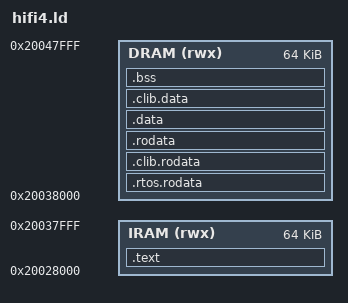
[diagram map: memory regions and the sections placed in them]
/* $Id$ */
/* Allwinner t113-s3 HiFi4 DSP memory layout */
/* Linker script to configure memory regions. */

MEMORY
{
	  IRAM (rwx)  : ORIGIN = 0x20028000, 			LENGTH = 64K	/* Cacheable DSP0 IRAM */
	  DRAM (rwx)  : ORIGIN = 0x20038000, 			LENGTH = 64K	/* Cacheable DSP0 DRAM */
}

/*ENTRY(Reset_Handler) */

SECTIONS
{
  .text : ALIGN(4)
  {
    _stext = .;
    _text_start = ABSOLUTE(.);
    *(.entry.text)
    *(.init.literal)
    KEEP(*(.init))
    *(.literal.sort.* SORT(.text.sort.*))
    KEEP (*(.literal.keepsort.* SORT(.text.keepsort.*) .literal.keep.* .text.keep.* .literal.*personality* .text.*personality*))
    *(.literal .text .literal.* .text.* .stub .gnu.warning .gnu.linkonce.literal.* .gnu.linkonce.t.*.literal .gnu.linkonce.t.*)
    *(.fini.literal)
    KEEP(*(.fini))
    *(.gnu.version)
    . = ALIGN (4);
    _text_end = ABSOLUTE(.);
    _etext = .;
  } >IRAM 
  
  .rtos.rodata : ALIGN(4)
  {
    _rtos_rodata_start = ABSOLUTE(.);
    *(.rtos.rodata)
    . = ALIGN (4);
    _rtos_rodata_end = ABSOLUTE(.);
  } >DRAM 

  .clib.rodata : ALIGN(4)
  {
    _clib_rodata_start = ABSOLUTE(.);
    *(.clib.rodata)
    . = ALIGN (4);
    _clib_rodata_end = ABSOLUTE(.);
  } >DRAM 

  .rodata : ALIGN(4)
  {
    _rodata_start = ABSOLUTE(.);
    *(.rodata)
    *(SORT(.rodata.sort.*))
    KEEP (*(SORT(.rodata.keepsort.*) .rodata.keep.*))
    *(.rodata.*)
    *(.gnu.linkonce.r.*)
    *(.rodata1)
    __XT_EXCEPTION_TABLE__ = ABSOLUTE(.);
    KEEP (*(.xt_except_table))
    KEEP (*(.gcc_except_table))
    *(.gnu.linkonce.e.*)
    *(.gnu.version_r)
    KEEP (*(.eh_frame))
    /*  C++ constructor and destructor tables, properly ordered:  */
    KEEP (*crtbegin.o(.ctors))
    KEEP (*(EXCLUDE_FILE (*crtend.o) .ctors))
    KEEP (*(SORT(.ctors.*)))
    KEEP (*(.ctors))
    KEEP (*crtbegin.o(.dtors))
    KEEP (*(EXCLUDE_FILE (*crtend.o) .dtors))
    KEEP (*(SORT(.dtors.*)))
    KEEP (*(.dtors))
    /*  C++ exception handlers table:  */
    __XT_EXCEPTION_DESCS__ = ABSOLUTE(.);
    *(.xt_except_desc)
    *(.gnu.linkonce.h.*)
    __XT_EXCEPTION_DESCS_END__ = ABSOLUTE(.);
    *(.xt_except_desc_end)
    *(.dynamic)
    *(.gnu.version_d)
    . = ALIGN(4);		/* this table MUST be 4-byte aligned */
    _bss_table_start = ABSOLUTE(.);
    LONG(_bss_start)
    LONG(_bss_end)
    _bss_table_end = ABSOLUTE(.);
    . = ALIGN (4);
    _rodata_end = ABSOLUTE(.);
  } >DRAM 

  .data : ALIGN(4)
  {
    _data_start = ABSOLUTE(.);
    *(.data)
    *(SORT(.data.sort.*))
    KEEP (*(SORT(.data.keepsort.*) .data.keep.*))
    *(.data.*)
    *(.gnu.linkonce.d.*)
    KEEP(*(.gnu.linkonce.d.*personality*))
    *(.data1)
    *(.sdata)
    *(.sdata.*)
    *(.gnu.linkonce.s.*)
    *(.sdata2)
    *(.sdata2.*)
    *(.gnu.linkonce.s2.*)
    KEEP(*(.jcr))
    *(__llvm_prf_cnts)
    *(__llvm_prf_data)
    *(__llvm_prf_vnds)
    . = ALIGN (4);
    _data_end = ABSOLUTE(.);
  } >DRAM 
  
  .clib.data : ALIGN(4)
  {
    _clib_data_start = ABSOLUTE(.);
    *(.clib.data)
    . = ALIGN (4);
    _clib_data_end = ABSOLUTE(.);
  } >DRAM 

  .bss (NOLOAD) : ALIGN(8)
  {
    . = ALIGN (8);
    _bss_start = ABSOLUTE(.);
    *(.dynsbss)
    *(.sbss)
    *(.sbss.*)
    *(.gnu.linkonce.sb.*)
    *(.scommon)
    *(.sbss2)
    *(.sbss2.*)
    *(.gnu.linkonce.sb2.*)
    *(.dynbss)
    *(.bss)
    *(SORT(.bss.sort.*))
    KEEP (*(SORT(.bss.keepsort.*) .bss.keep.*))
    *(.bss.*)
    *(.gnu.linkonce.b.*)
    *(COMMON)
    *(.clib.bss)
    *(.clib.percpu.bss)
    *(.rtos.percpu.bss)
    *(.rtos.bss)
    *(.dram0.bss)
    . = ALIGN (8);
    _bss_end = ABSOLUTE(.);
    _end = ALIGN(0x8);
    PROVIDE(end = ALIGN(0x8));
    _stack_sentry = ALIGN(0x8);
    _memmap_seg_dram0_0_end = ALIGN(0x8);
  } >DRAM 
}

__StackTop = ORIGIN(DRAM) + LENGTH(DRAM);
PROVIDE(__stack = __StackTop);

